VERSION "VehicleGPT EV 1.0"

NS_ :

BS_:

BU_: VCU BMS HVAC TPMS COLLECTOR

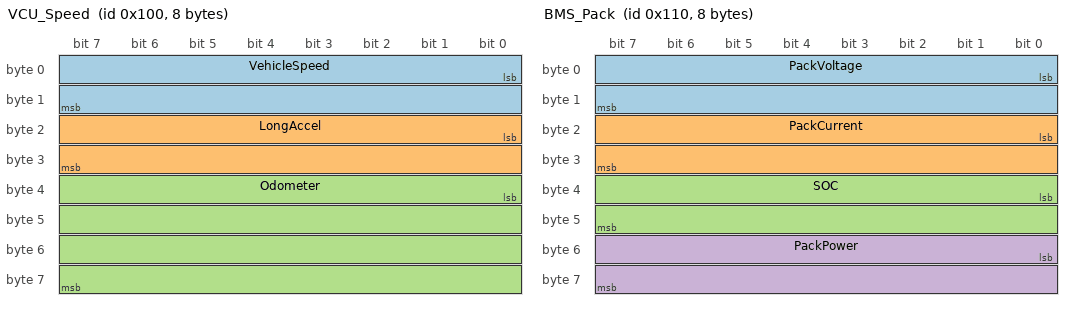
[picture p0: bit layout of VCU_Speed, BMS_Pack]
BO_ 256 VCU_Speed: 8 VCU
 SG_ VehicleSpeed : 0|16@1+ (0.01,0) [0|655.35] "km/h" COLLECTOR
 SG_ LongAccel : 16|16@1- (0.001,0) [-32.768|32.767] "m/s2" COLLECTOR
 SG_ Odometer : 32|32@1+ (0.001,0) [0|4294967.295] "km" COLLECTOR

BO_ 272 BMS_Pack: 8 BMS
 SG_ PackVoltage : 0|16@1+ (0.1,0) [0|6553.5] "V" COLLECTOR
 SG_ PackCurrent : 16|16@1- (0.1,0) [-3276.8|3276.7] "A" COLLECTOR
 SG_ SOC : 32|16@1+ (0.01,0) [0|100] "%" COLLECTOR
 SG_ PackPower : 48|16@1- (0.01,0) [-327.68|327.67] "kW" COLLECTOR

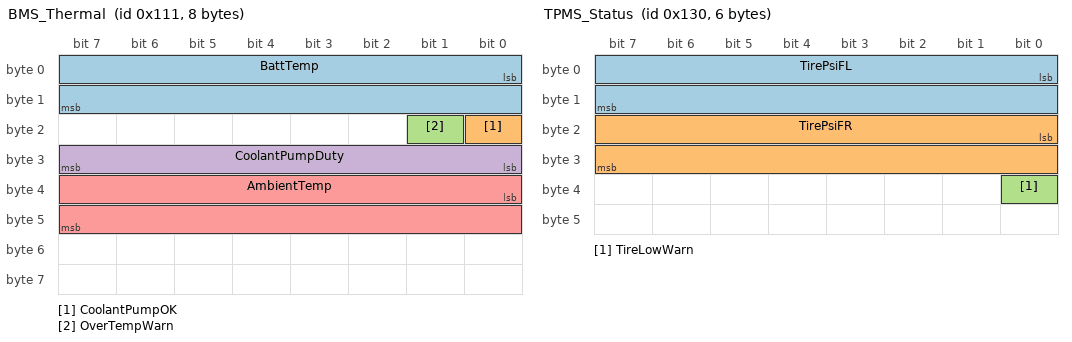
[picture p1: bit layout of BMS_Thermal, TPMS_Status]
BO_ 273 BMS_Thermal: 8 BMS
 SG_ BattTemp : 0|16@1- (0.01,0) [-327.68|327.67] "degC" COLLECTOR
 SG_ CoolantPumpOK : 16|1@1+ (1,0) [0|1] "" COLLECTOR
 SG_ OverTempWarn : 17|1@1+ (1,0) [0|1] "" COLLECTOR
 SG_ CoolantPumpDuty : 24|8@1+ (1,0) [0|100] "%" COLLECTOR
 SG_ AmbientTemp : 32|16@1- (0.1,0) [-3276.8|3276.7] "degC" COLLECTOR

BO_ 288 HVAC_Status: 4 HVAC
 SG_ AcPower : 0|16@1+ (0.001,0) [0|65.535] "kW" COLLECTOR
 SG_ CabinSetTemp : 16|8@1+ (0.5,0) [0|127.5] "degC" COLLECTOR

BO_ 304 TPMS_Status: 6 TPMS
 SG_ TirePsiFL : 0|16@1+ (0.01,0) [0|655.35] "psi" COLLECTOR
 SG_ TirePsiFR : 16|16@1+ (0.01,0) [0|655.35] "psi" COLLECTOR
 SG_ TireLowWarn : 32|1@1+ (1,0) [0|1] "" COLLECTOR

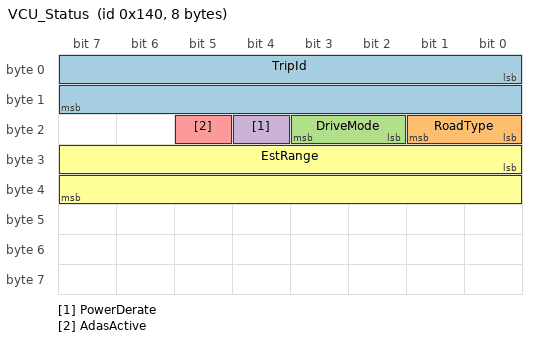
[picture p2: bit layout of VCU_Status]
BO_ 320 VCU_Status: 8 VCU
 SG_ TripId : 0|16@1+ (1,0) [0|65535] "" COLLECTOR
 SG_ RoadType : 16|2@1+ (1,0) [0|3] "" COLLECTOR
 SG_ DriveMode : 18|2@1+ (1,0) [0|3] "" COLLECTOR
 SG_ PowerDerate : 20|1@1+ (1,0) [0|1] "" COLLECTOR
 SG_ AdasActive : 21|1@1+ (1,0) [0|1] "" COLLECTOR
 SG_ EstRange : 24|16@1+ (0.1,0) [0|6553.5] "km" COLLECTOR

CM_ BO_ 256 "Vehicle dynamics from VCU, 10 Hz";
CM_ BO_ 272 "Battery pack electrical state, 10 Hz";
CM_ BO_ 273 "Battery thermal state, 10 Hz";
CM_ BO_ 320 "Vehicle status and context, 10 Hz";
VAL_ 320 RoadType 0 "CITY" 1 "HIGHWAY" ;
VAL_ 320 DriveMode 0 "NORMAL" 1 "AGGRESSIVE" ;
